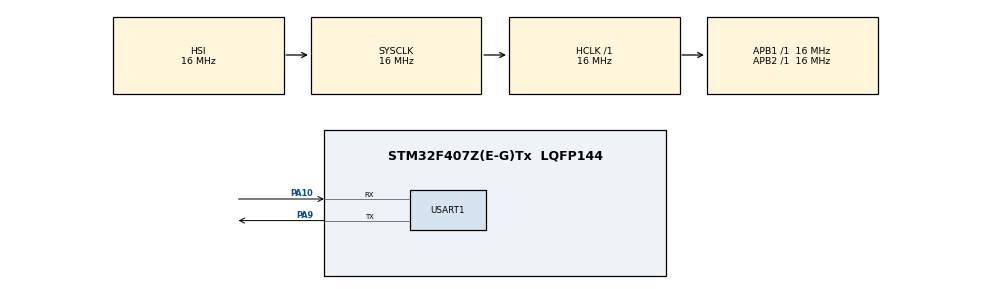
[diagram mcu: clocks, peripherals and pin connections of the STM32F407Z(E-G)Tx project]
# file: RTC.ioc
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Mcu.Family=STM32F4
Mcu.Name=STM32F407Z(E-G)Tx
Mcu.Package=LQFP144
NVIC.PriorityGroup=NVIC_PRIORITYGROUP_4
NVIC.RTC_WKUP_IRQn=true\:0\:0\:false\:false\:true\:true\:true\:true
PA10.Mode=Asynchronous
PA10.Signal=USART1_RX
PA9.Mode=Asynchronous
PA9.Signal=USART1_TX
PC14-OSC32_IN.Mode=LSE-External-Oscillator
PC14-OSC32_IN.Signal=RCC_OSC32_IN
PC15-OSC32_OUT.Mode=LSE-External-Oscillator
PC15-OSC32_OUT.Signal=RCC_OSC32_OUT
PH0-OSC_IN.Mode=HSE-External-Oscillator
PH0-OSC_IN.Signal=RCC_OSC_IN
PH1-OSC_OUT.Mode=HSE-External-Oscillator
PH1-OSC_OUT.Signal=RCC_OSC_OUT
ProjectManager.HeapSize=0x200
ProjectManager.StackSize=0x400
ProjectManager.TargetToolchain=MDK-ARM V5.32
RCC.AHBFreq_Value=16000000
RCC.APB1Freq_Value=16000000
RCC.APB2Freq_Value=16000000
RCC.CortexFreq_Value=16000000
RCC.HSE_VALUE=25000000
RCC.HSI_VALUE=16000000
RCC.SYSCLKFreq_VALUE=16000000
RCC.VCOOutputFreq_Value=192000000
RTC.AsynchPrediv=0x7f
RTC.Date=24
RTC.Format=RTC_FORMAT_BCD
RTC.Hours=17
RTC.Minutes=30
RTC.Month=RTC_MONTH_MARCH
RTC.SynchPrediv=0xff
RTC.WakeUpClock=RTC_WAKEUPCLOCK_RTCCLK_DIV16
RTC.WakeUpCounter=0
RTC.WeekDay=RTC_WEEKDAY_FRIDAY
RTC.Year=24
USART1.VirtualMode=VM_ASYNC
VP_RTC_VS_RTC_Activate.Mode=RTC_Enabled
VP_RTC_VS_RTC_Calendar.Mode=RTC_Calendar
VP_RTC_VS_RTC_WakeUp_intern.Mode=WakeUp
board=custom

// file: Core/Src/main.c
/* USER CODE BEGIN Header */
/**
  ******************************************************************************
  * @file           : main.c
  * @brief          : Main program body
  ******************************************************************************
  * @attention
  *
  * Copyright (c) 2024 STMicroelectronics.
  * All rights reserved.
  *
  * This software is licensed under terms that can be found in the LICENSE file
  * in the root directory of this software component.
  * If no LICENSE file comes with this software, it is provided AS-IS.
  *
  ******************************************************************************
  */
/* USER CODE END Header */
#include "main.h"
#include "rtc.h"
#include "usart.h"
#include "gpio.h"

/* USER CODE BEGIN Includes */
#include <stdio.h>
/* USER CODE END Includes */

/* USER CODE BEGIN PV */
int fputc(int ch, FILE *f)
{
  HAL_UART_Transmit(&huart1, (uint8_t *)&ch, 1, 0xffff);
  return ch;
}
/* USER CODE END PV */

void SystemClock_Config(void);

int main(void)
{

  /* USER CODE BEGIN 1 */
	uint8_t t = 0;
	char tbuf[40];
	RTC_DateTypeDef RTC_DateStruct;
	RTC_TimeTypeDef RTC_TimeStruct;

  /* USER CODE END 1 */

  /* MCU Configuration--------------------------------------------------------*/

  /* Reset of all peripherals, Initializes the Flash interface and the Systick. */
  HAL_Init();

  /* Configure the system clock */
  SystemClock_Config();

  /* Initialize all configured peripherals */
  MX_GPIO_Init();
  MX_RTC_Init();
  MX_USART1_UART_Init();

  /* Infinite loop */
  /* USER CODE BEGIN WHILE */
  while (1)
  {
		HAL_RTC_GetTime(&hrtc,&RTC_TimeStruct,RTC_FORMAT_BIN);
		sprintf((char*)tbuf,"Time:%02d:%02d:%02d",RTC_TimeStruct.Hours,RTC_TimeStruct.Minutes,RTC_TimeStruct.Seconds);
		printf("%s\r\n", tbuf);
		//print_uint8_array(tbuf, 40);
		HAL_RTC_GetDate(&hrtc,&RTC_DateStruct,RTC_FORMAT_BIN);
		sprintf((char*)tbuf,"Date:20%02d-%02d-%02d",RTC_DateStruct.Year,RTC_DateStruct.Month,RTC_DateStruct.Date);
		printf("%s\r\n", tbuf);
		sprintf((char*)tbuf,"Week:%d",RTC_DateStruct.WeekDay);
		printf("%s\r\n", tbuf);
		HAL_Delay(1000);
    /* USER CODE END WHILE */

  }
}

void SystemClock_Config(void)
{
  RCC_OscInitTypeDef RCC_OscInitStruct = {0};
  RCC_ClkInitTypeDef RCC_ClkInitStruct = {0};

  /** Configure the main internal regulator output voltage
  */
  __HAL_RCC_PWR_CLK_ENABLE();
  __HAL_PWR_VOLTAGESCALING_CONFIG(PWR_REGULATOR_VOLTAGE_SCALE1);

  /** Initializes the RCC Oscillators according to the specified parameters
  * in the RCC_OscInitTypeDef structure.
  */
  RCC_OscInitStruct.OscillatorType = RCC_OSCILLATORTYPE_HSI|RCC_OSCILLATORTYPE_LSI;
  RCC_OscInitStruct.HSIState = RCC_HSI_ON;
  RCC_OscInitStruct.HSICalibrationValue = RCC_HSICALIBRATION_DEFAULT;
  RCC_OscInitStruct.LSIState = RCC_LSI_ON;
  RCC_OscInitStruct.PLL.PLLState = RCC_PLL_NONE;
  if (HAL_RCC_OscConfig(&RCC_OscInitStruct) != HAL_OK)
  {
    Error_Handler();
  }

  /** Initializes the CPU, AHB and APB buses clocks
  */
  RCC_ClkInitStruct.ClockType = RCC_CLOCKTYPE_HCLK|RCC_CLOCKTYPE_SYSCLK
                              |RCC_CLOCKTYPE_PCLK1|RCC_CLOCKTYPE_PCLK2;
  RCC_ClkInitStruct.SYSCLKSource = RCC_SYSCLKSOURCE_HSI;
  RCC_ClkInitStruct.AHBCLKDivider = RCC_SYSCLK_DIV1;
  RCC_ClkInitStruct.APB1CLKDivider = RCC_HCLK_DIV1;
  RCC_ClkInitStruct.APB2CLKDivider = RCC_HCLK_DIV1;

  if (HAL_RCC_ClockConfig(&RCC_ClkInitStruct, FLASH_LATENCY_0) != HAL_OK)
  {
    Error_Handler();
  }
}

void Error_Handler(void)
{
  __disable_irq();
  while (1)
  {
  }
}
